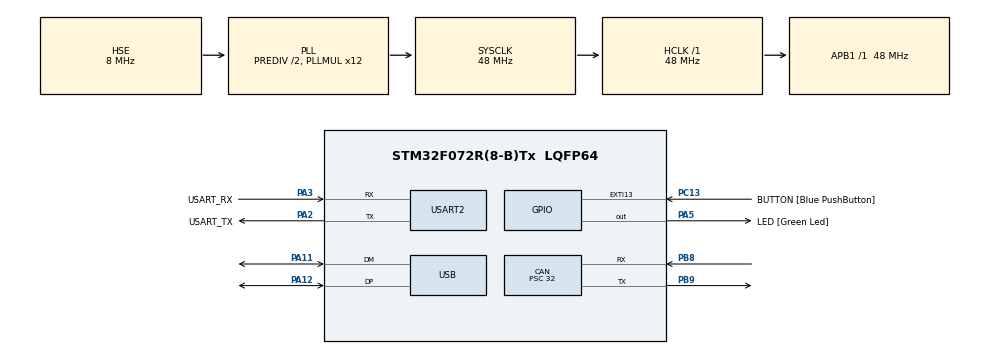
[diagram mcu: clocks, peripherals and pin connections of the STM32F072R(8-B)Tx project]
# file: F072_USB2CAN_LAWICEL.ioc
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Mcu.Family=STM32F0
PC15-OSC32_OUT.Mode=LSE-External-Oscillator
PA2.GPIO_PuPd=GPIO_NOPULL
USB_DEVICE.CLASS_NAME_FS=CDC
NVIC.USB_IRQn=true\:0\:0\:false\:false\:true\:false\:true
USB_DEVICE.VirtualModeFS=Cdc_FS
PC13.Signal=GPXTI13
USB_DEVICE.PID_CDC_FS=0x5740
PA14.GPIO_Label=TCK
PA3.GPIO_PuPd=GPIO_NOPULL
PA2.GPIO_Speed=GPIO_SPEED_FREQ_LOW
VP_RTC_VS_RTC_Activate.Mode=RTC_Enabled
PA11.Mode=Device
PC13.GPIO_Label=BUTTON [Blue PushButton]
PC14-OSC32_IN.Signal=RCC_OSC32_IN
PA3.GPIO_Speed=GPIO_SPEED_FREQ_LOW
USB.lpm_enable=DISABLE
RCC.SYSCLKSource=RCC_SYSCLKSOURCE_PLLCLK
ProjectManager.StackSize=0x400
PA3.Mode=Asynchronous
PA13.Signal=SYS_SWDIO
PA12.Signal=USB_DP
CAN.BS2=CAN_BS2_5TQ
CAN.BS1=CAN_BS1_6TQ
CAN.Prescaler=32
USB_DEVICE.VID=0x483
ProjectManager.TargetToolchain=STM32CubeIDE
PA3.GPIO_Mode=GPIO_MODE_AF_PP
RCC.HCLKFreq_Value=48000000
VP_USB_DEVICE_VS_USB_DEVICE_CDC_FS.Mode=CDC_FS
PB9.Mode=Master
RCC.PLLDivider=RCC_PREDIV_DIV2
CAN.Mode=CAN_MODE_NORMAL
PC15-OSC32_OUT.Signal=RCC_OSC32_OUT
RCC.AHBFreq_Value=48000000
PF0-OSC_IN.Mode=HSE-External-Clock-Source
RCC.PREFETCH_ENABLE-AdvancedSettings=1
PA5.Signal=GPIO_Output
RTC.Minutes=37
board=NUCLEO-F072RB
USART2.VirtualMode-Asynchronous=VM_ASYNC
RCC.PLLMUL=RCC_PLL_MUL12
PC14-OSC32_IN.Mode=LSE-External-Oscillator
PA14.Mode=Serial_Wire
PA5.GPIO_PuPd=GPIO_NOPULL
PA13.Mode=Serial_Wire
Mcu.Name=STM32F072R(8-B)Tx
CAN.CalculateTimeQuantum=666.6666666666666
PA2.Signal=USART2_TX
PA13.GPIO_Label=TMS
RCC.FLatency-AdvancedSettings=FLASH_LATENCY_1
NVIC.CEC_CAN_IRQn=true\:0\:0\:false\:false\:true\:true\:true
RCC.SYSCLKFreq_VALUE=48000000
RTC.Hours=0
Mcu.Package=LQFP64
PB9.Signal=CAN_TX
PA12.Mode=Device
PA5.GPIO_Label=LED [Green Led]
PC13.GPIO_ModeDefaultEXTI=GPIO_MODE_IT_FALLING
USART2.VirtualMode=VM_ASYNC
PA2.GPIO_Label=USART_TX
PA11.Signal=USB_DM
PA14.Signal=SYS_SWCLK
VP_RTC_VS_RTC_Calendar.Mode=RTC_Calendar
ProjectManager.HeapSize=0x200
PA5.GPIO_Speed=GPIO_SPEED_FREQ_LOW
PB8.Mode=Master
RCC.APB1TimFreq_Value=48000000
PA2.Mode=Asynchronous
PB8.Signal=CAN_RX
PF0-OSC_IN.Signal=RCC_OSC_IN
RCC.APB1Freq_Value=48000000
PA5.GPIO_Mode=GPIO_MODE_OUTPUT_PP
USB_DEVICE.VirtualMode=Cdc
RCC.USBClockSelection=RCC_USBCLKSOURCE_PLL
PF1-OSC_OUT.Signal=RCC_OSC_OUT
PA3.GPIO_Label=USART_RX
PA3.Signal=USART2_RX
PA2.GPIO_Mode=GPIO_MODE_AF_PP

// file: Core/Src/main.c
/* USER CODE BEGIN Header */
/**
 ******************************************************************************
 * @file           : main.c
 * @brief          : Main program body
 ******************************************************************************
 * @attention
 *
 * <h2><center>&copy; Copyright (c) 2020 STMicroelectronics.
 * All rights reserved.</center></h2>
 *
 * This software component is licensed by ST under BSD 3-Clause license,
 * the "License"; You may not use this file except in compliance with the
 * License. You may obtain a copy of the License at:
 *                        opensource.org/licenses/BSD-3-Clause
 *
 ******************************************************************************
 */
/* USER CODE END Header */
#include "main.h"
#include "can.h"
#include "rtc.h"
#include "usart.h"
#include "usb_device.h"
#include "gpio.h"

/* USER CODE BEGIN Includes */

#include "lawicel.h"
#include "ucanopen.h"

#include "ui.h"

/* USER CODE END Includes */

void SystemClock_Config(void);

int main(void)
{

  /* MCU Configuration--------------------------------------------------------*/

  /* Reset of all peripherals, Initializes the Flash interface and the Systick. */
  HAL_Init();

  /* Configure the system clock */
  SystemClock_Config();

  /* Initialize all configured peripherals */
  MX_GPIO_Init();
  MX_USART2_UART_Init();
  MX_CAN_Init();
  MX_USB_DEVICE_Init();
  MX_RTC_Init();
  /* USER CODE BEGIN 2 */

  	/* VERSION: 1.0 */

	/* Clock */
	set_time(946730096);   // Sat, 01 Aug 2020 13:37:00 GMT

	/* User interface */
	*pUserLed = signal_init(LED_GPIO_Port, LED_Pin, SignalActiveLevel_HIGH, 1);
	*pUserButton = button_init(BUTTON_GPIO_Port, BUTTON_Pin, ButtonActiveLevel_LOW, 1);

	LAWICEL_init(pLawicelInstance, NULL, &hcan);

	/* uCANopen init */
	uco_init(&uCO, uCO_OD);
	uCO.NodeState = NODE_STATE_OPERATIONAL; //FIXME!

  /* USER CODE END 2 */

  /* Infinite loop */
  /* USER CODE BEGIN WHILE */
	while (1)
	{
		LAWICEL_run(pLawicelInstance);

    /* USER CODE END WHILE */

    /* USER CODE BEGIN 3 */

		uco_run(&uCO);
	}
  /* USER CODE END 3 */
}

void SystemClock_Config(void)
{
  RCC_OscInitTypeDef RCC_OscInitStruct = {0};
  RCC_ClkInitTypeDef RCC_ClkInitStruct = {0};
  RCC_PeriphCLKInitTypeDef PeriphClkInit = {0};

  /** Initializes the RCC Oscillators according to the specified parameters
  * in the RCC_OscInitTypeDef structure.
  */
  RCC_OscInitStruct.OscillatorType = RCC_OSCILLATORTYPE_LSI|RCC_OSCILLATORTYPE_HSE;
  RCC_OscInitStruct.HSEState = RCC_HSE_BYPASS;
  RCC_OscInitStruct.LSIState = RCC_LSI_ON;
  RCC_OscInitStruct.PLL.PLLState = RCC_PLL_ON;
  RCC_OscInitStruct.PLL.PLLSource = RCC_PLLSOURCE_HSE;
  RCC_OscInitStruct.PLL.PLLMUL = RCC_PLL_MUL12;
  RCC_OscInitStruct.PLL.PREDIV = RCC_PREDIV_DIV2;
  if (HAL_RCC_OscConfig(&RCC_OscInitStruct) != HAL_OK)
  {
    Error_Handler();
  }
  /** Initializes the CPU, AHB and APB buses clocks
  */
  RCC_ClkInitStruct.ClockType = RCC_CLOCKTYPE_HCLK|RCC_CLOCKTYPE_SYSCLK
                              |RCC_CLOCKTYPE_PCLK1;
  RCC_ClkInitStruct.SYSCLKSource = RCC_SYSCLKSOURCE_PLLCLK;
  RCC_ClkInitStruct.AHBCLKDivider = RCC_SYSCLK_DIV1;
  RCC_ClkInitStruct.APB1CLKDivider = RCC_HCLK_DIV1;

  if (HAL_RCC_ClockConfig(&RCC_ClkInitStruct, FLASH_LATENCY_1) != HAL_OK)
  {
    Error_Handler();
  }
  PeriphClkInit.PeriphClockSelection = RCC_PERIPHCLK_USB|RCC_PERIPHCLK_USART2
                              |RCC_PERIPHCLK_RTC;
  PeriphClkInit.Usart2ClockSelection = RCC_USART2CLKSOURCE_PCLK1;
  PeriphClkInit.RTCClockSelection = RCC_RTCCLKSOURCE_LSI;
  PeriphClkInit.UsbClockSelection = RCC_USBCLKSOURCE_PLL;

  if (HAL_RCCEx_PeriphCLKConfig(&PeriphClkInit) != HAL_OK)
  {
    Error_Handler();
  }
}

void Error_Handler(void)
{
  /* USER CODE BEGIN Error_Handler_Debug */
	/* User can add his own implementation to report the HAL error return state */
	while (1)
	{
		HAL_GPIO_TogglePin(LED_GPIO_Port, LED_Pin);
		HAL_Delay(200);
	}
  /* USER CODE END Error_Handler_Debug */
}

/************************ (C) COPYRIGHT STMicroelectronics *****END OF FILE****/
